# STM32MP13xx register map
File version: 1.7
CPU: CA7 r0p0, little endian, MPU, FPU, 4 interrupt priority bits
Registers are 32-bit, read-write, reset 0x0 unless marked. A register's access mark holds for its fields unless they carry their own. Offsets are from the block's base; [hi:lo] are bit positions; lines under a group give offsets from that group; {n}, {i} and the like mark numbered series.

## GICH — GICH address block description
Base 0xA0024000
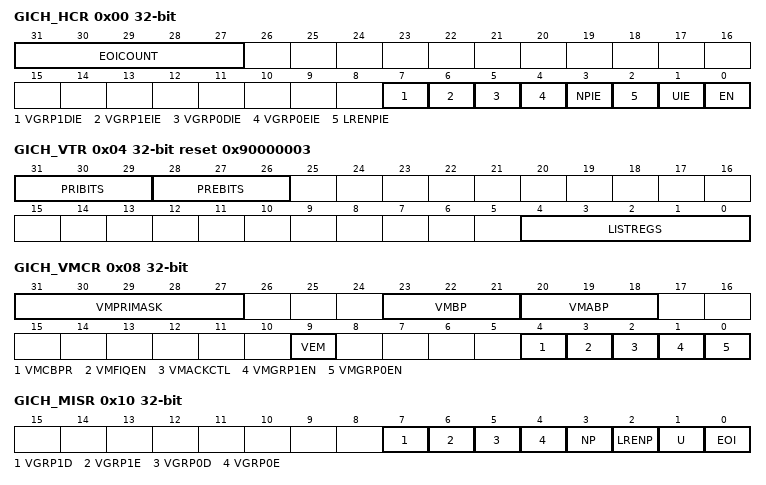
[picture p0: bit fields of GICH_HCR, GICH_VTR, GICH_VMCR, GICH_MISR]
0x00 GICH_HCR — GICH hypervisor control register
  [31:27] EOICOUNT — end-of-interrupt counter Counts the number of EOIs received that do not have a corresponding entry in the list registers. The virtual CPU interface increments this field automatically when a matching EOI is received. When EOIs that do not clear a bit in the active priorities register, GICH_APR does not cause an increment. Although not possible under correct operation, if an EOI occurs when the value of this field is 31, this field wraps to 0. The maintenance interrupt is asserted whenever this field is non-zero and the LRENPIE bit is set to 1.
  [7] VGRP1DIE — virtual machine disable group 1 interrupt enable Enables the signaling of a maintenance interrupt while signaling of group 1 interrupts from the virtual CPU interface to the connected virtual machine, is disabled.
  [6] VGRP1EIE — virtual machine enable group 1 interrupt enable Enables the signaling of a maintenance interrupt while signaling of group 1 interrupts from the virtual CPU interface to the connected virtual machine, is enabled.
  [5] VGRP0DIE — virtual machine disable group 0interrupt enable Enables the signaling of a maintenance interrupt while signaling of group 0interrupts from the virtual CPU interface to the connected virtual machine, is disabled.
  [4] VGRP0EIE — virtual machine enable group 0interrupt enable Enables the signaling of a maintenance interrupt while signaling of group 0interrupts from the virtual CPU interface to the connected virtual machine, is enabled.
  [3] NPIE — no pending interrupt enable Enables the signaling of a maintenance interrupt while no pending interrupts are present in the list registers.
  [2] LRENPIE — list register entry not present interrupt enable Enables the signaling of a maintenance interrupt while the virtual CPU interface does not have a corresponding valid list register entry for an EOI request.
  [1] UIE — underflow interrupt enable. Enables the signaling of a maintenance interrupt when the list registers are empty, or hold only one valid entry.
  [0] EN — global enable bit for the virtual CPU interface
0x04 GICH_VTR ro reset 0x90000003
  [31:29] PRIBITS — priority bits Indicates the number of priority bits implemented, minus one. For example, 0x4 means 5 bits of priority and 32 priority levels.
  [28:26] PREBITS — preemption bits Indicates the number of preemption bits implemented, minus one. For example, 0x4 means 5 bits of preemption and 32 preemption levels
  [4:0] LISTREGS — list registers Indicates the number of implemented list registers, minus one. For example, 0x3 means 4 list registers.
0x08 GICH_VMCR — GICH virtual machine control register
  [31:27] VMPRIMASK — alias of GICV_PMR.PRIORITY
  [23:21] VMBP — alias of GICV_BPR.BINARY_POINT
  [20:18] VMABP — alias of GICV_ABPR.BINARY_POINT.
  [9] VEM — alias of GICV_CTLR.EOIMODE
  [4] VMCBPR — alias of GICV_CTLR.CBPR
  [3] VMFIQEN — alias of GICV_CTLR.FIQEN
  [2] VMACKCTL — alias of GICV_CTLR.ACKCTL
  [1] VMGRP1EN — alias of GICV_CTLR.ENABLEGRP1
  [0] VMGRP0EN — alias of GICV_CTLR.ENABLEGRP0
0x10 GICH_MISR ro — GICH maintenance interrupt status register
  [7] VGRP1D — disabled group 1 maintenance interrupt Asserted whenever GICH_HCR.VGRP1DIE is set and GICH_VMCR.VMGRP1EN=0.
  [6] VGRP1E — enabled group 1 maintenance interrupt Asserted whenever GICH_HCR.VGRP1EIE is set and GICH_VMCR.VMGRP1EN=1.
  [5] VGRP0D — disabled group 0 maintenance interrupt Asserted whenever GICH_HCR.VGRP0DIE is set and GICH_VMCR.VMGRP0EN=0.
  [4] VGRP0E — enabled group 0 maintenance interrupt Asserted whenever GICH_HCR.VGRP0EIE is set and GICH_VMCR.VMGRP0EN=1.
  [3] NP — no pending maintenance interrupt Asserted whenever GICH_HCR.NPIE=1 and no list register is in pending state.
  [2] LRENP — list register entry not present maintenance interrupt Asserted whenever GICH_HCR.LRENPIE=1 and GICH_HCR.EOICOUNT is non-zero.
  [1] U — underflow maintenance interrupt Asserted whenever GICH_HCR.UIE is set and if none, or only one, of the list register entries are marked as a valid interrupt, that is, if the corresponding GICH_LRx.STATE bits do not equal 0x0.
  [0] EOI — End of interrupt maintenance interrupt Asserted whenever at least one list register is asserting an EOI Interrupt., which means at least one bit in GICH_EISRx=1.
0x20 GICH_EISR0 ro — GICH end of interrupt status register
  [31:0] EISR0 — end of interrupt status
0x30 GICH_ELSR0 ro — GICH empty list status register
  [31:0] ELSR0 — empty list status
0xF0 GICH_APR0
  [31:0] APR0 — active priority
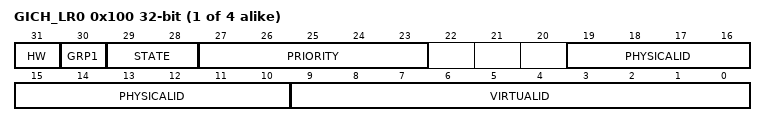
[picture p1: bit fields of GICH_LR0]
{0x100+4i} GICH_LR{i} (i=0..3)
  [31] HW — hardware interrupt Indicates whether this virtual interrupt is a hardware interrupt, meaning that it corresponds to a physical interrupt. Deactivation of the virtual interrupt also causes the deactivation of the physical interrupt with the ID that the PhysicalID field indicates.
  [30] GRP1 — Indicates whether this virtual interrupt is a group 1 virtual interrupt
  [29:28] STATE — state of the interrupt
  [27:23] PRIORITY — priority of the interrupt
  [19:10] PHYSICALID — physical ID The function of this bit depends on the value of the GICH_LR.HW bit, as follows. 1) When GICH_LR.HW is set to 0, bits [9:0] have the following meanings: - [19] EOI when this interrupt triggers an EOI maintenance interrupt - [12:10] CPUID If the interrupt has the VirtualID for an SGI, that is, 0-15. This field shows the requesting CPU ID. This appears in the relevant field of the virtual machine interrupt acknowledge register, GICV_IAR or GICV_AIAR. Otherwise, this field must be set to 0. 2) When GICH_LR.HW is set to 1, PHYSICALID[9:0] indicates the physical interrupt ID that the hypervisor forwards to the GICD. If the value of PHYSICALID is 0-15, or 1020-1023, behavior is unpredictable. If the value of PHYSICALID is 16-31, this field applies to the PPI associated with the same physical CPUID as the virtual CPU interface requesting the deactivation.
  [9:0] VIRTUALID — virtual ID This ID is returned to the guest OS when the interrupt is acknowledged through the VM interrupt acknowledge register, GICV_IAR. Each valid interrupt stored in the list registers must have a unique virtual ID for that virtual CPU interface. If the value of VIRTUALID is 1020-1023, behavior is unpredictable.
